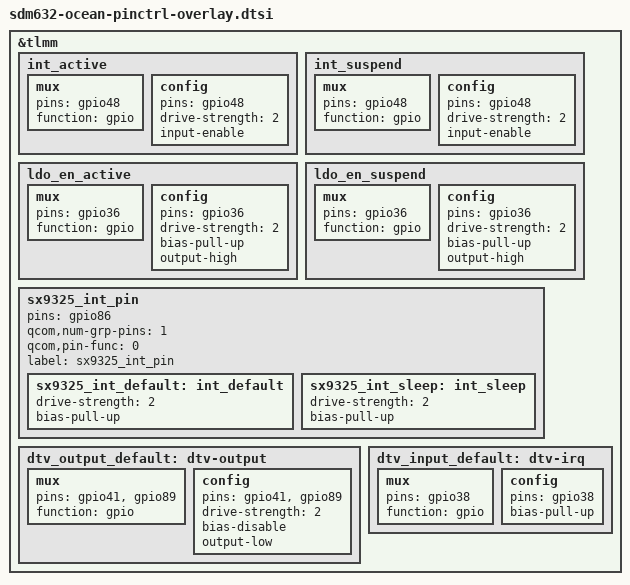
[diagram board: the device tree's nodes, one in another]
/*
 * Copyright (c) 2018, The Linux Foundation. All rights reserved.
 *
 * This program is free software; you can redistribute it and/or modify
 * it under the terms of the GNU General Public License version 2 and
 * only version 2 as published by the Free Software Foundation.
 *
 * This program is distributed in the hope that it will be useful,
 * but WITHOUT ANY WARRANTY; without even the implied warranty of
 * MERCHANTABILITY or FITNESS FOR A PARTICULAR PURPOSE.  See the
 * GNU General Public License for more details.
 */
&tlmm{
	int_active: int_active {
		/* INTERRUPT */
		mux {
			pins = "gpio48";
			function = "gpio";
		};

		config {
			pins = "gpio48";
			drive-strength = <2>; /* 2 MA */
			input-enable;
		};
	};

	int_suspend: int_suspend{
		/* INTERRUPT */
		mux {
			pins = "gpio48";
			function = "gpio";
		};

		config {
			pins = "gpio48";
			drive-strength = <2>; /* 2 MA */
			input-enable;
		};
	};

	ldo_en_active: ldo_en_active {
		/* LDO ENABLE */
		mux {
			pins = "gpio36";
			function = "gpio";
		};

		config {
			pins = "gpio36";
			drive-strength = <2>; /* 2 MA */
			bias-pull-up; /* pull up */
			output-high;
		};
	};

	ldo_en_suspend: ldo_en_suspend {
		/* LDO ENABLE */
		mux {
			pins = "gpio36";
			function = "gpio";
		};

		config {
			pins = "gpio36";
			drive-strength = <2>; /* 2 MA */
			bias-pull-up; /* pull up */
			output-high;
		};
	};

	sx9325_int_pin {
		/* qcom,pins = <&gp 86>;*/
		pins = "gpio86";
		qcom,num-grp-pins = <1>;
		qcom,pin-func = <0>;
		label = "sx9325_int_pin";
		sx9325_int_default: int_default {
			drive-strength = <2>;
			bias-pull-up;
		};
		sx9325_int_sleep: int_sleep {
			drive-strength = <2>;
			bias-pull-up;
		};
	};

	dtv_output_default: dtv-output {
		mux {
			/* enable, reset */
			pins = "gpio41", "gpio89";
			function = "gpio";
		};
		config {
			pins = "gpio41", "gpio89";
			drive-strength = <2>; /* 2 MA */
			bias-disable ; /* No PULL */
			output-low;
		};
	};
	/* DTV interrupt pin */
	dtv_input_default: dtv-irq {
		mux {
			pins = "gpio38";
			function = "gpio";
		};
		config {
			pins = "gpio38";
			bias-pull-up; /* pull up */
		};
	};
};
